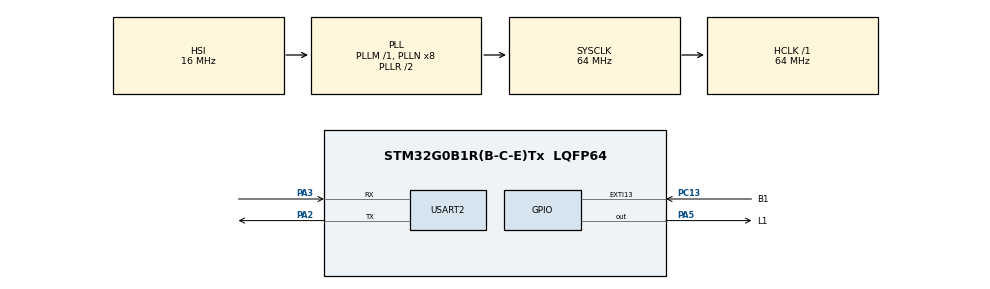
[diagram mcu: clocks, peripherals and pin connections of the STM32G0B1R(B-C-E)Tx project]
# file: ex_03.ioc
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Mcu.Family=STM32G0
Mcu.Name=STM32G0B1R(B-C-E)Tx
Mcu.Package=LQFP64
NVIC.EXTI4_15_IRQn=true\:0\:0\:false\:false\:true\:true\:true
NVIC.USART2_LPUART2_IRQn=true\:0\:0\:false\:false\:true\:true\:true
PA13.Mode=Serial_Wire
PA13.Signal=SYS_SWDIO
PA14-BOOT0.Mode=Serial_Wire
PA14-BOOT0.Signal=SYS_SWCLK
PA2.Mode=Asynchronous
PA2.Signal=USART2_TX
PA3.Mode=Asynchronous
PA3.Signal=USART2_RX
PA5.GPIO_Label=L1
PA5.PinState=GPIO_PIN_RESET
PA5.Signal=GPIO_Output
PC13.GPIO_Label=B1
PC13.GPIO_ModeDefaultEXTI=GPIO_MODE_IT_RISING_FALLING
PC13.Signal=GPXTI13
ProjectManager.HeapSize=0x200
ProjectManager.StackSize=0x400
ProjectManager.TargetToolchain=STM32CubeIDE
RCC.ADCFreq_Value=64000000
RCC.AHBFreq_Value=64000000
RCC.CortexFreq_Value=64000000
RCC.EXTERNAL_CLOCK_VALUE=48000
RCC.HCLKFreq_Value=64000000
RCC.HSE_VALUE=8000000
RCC.HSI48_VALUE=48000000
RCC.HSI_VALUE=16000000
RCC.LSE_VALUE=32768
RCC.SYSCLKFreq_VALUE=64000000
RCC.SYSCLKSource=RCC_SYSCLKSOURCE_PLLCLK
RCC.USBFreq_Value=48000000
RCC.VCOOutputFreq_Value=128000000
USART2.VirtualMode-Asynchronous=VM_ASYNC
VP_SYS_VS_DBSignals.Mode=DisableDeadBatterySignals
board=custom

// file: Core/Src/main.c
/* USER CODE BEGIN Header */
/**
  ******************************************************************************
  * @file           : main.c
  * @brief          : Main program body
  ******************************************************************************
  * @attention
  *
  * Copyright (c) 2022 STMicroelectronics.
  * All rights reserved.
  *
  * This software is licensed under terms that can be found in the LICENSE file
  * in the root directory of this software component.
  * If no LICENSE file comes with this software, it is provided AS-IS.
  *
  ******************************************************************************
  */
/* USER CODE END Header */
#include "main.h"

/* USER CODE BEGIN Includes */
#include<stdint.h>
#include<stdio.h>
#include<stdlib.h>
#include<string.h>
/* USER CODE END Includes */

/* USER CODE BEGIN PTD */
uint16_t count = 0;
uint8_t pres = 0;
char text[80];
/* USER CODE END PTD */

UART_HandleTypeDef huart2;

void SystemClock_Config(void);
static void MX_GPIO_Init(void);
static void MX_USART2_UART_Init(void);

/* USER CODE BEGIN 0 */
void HAL_GPIO_EXTI_Rising_Callback(uint16_t GPIO_Pin){
	count++;
	sprintf(text,"B1 presionado %d, ", count);
	HAL_UART_Transmit_IT(&huart2, &text, strlen(text));
}
/* USER CODE END 0 */

int main(void)
{

  /* MCU Configuration--------------------------------------------------------*/

  /* Reset of all peripherals, Initializes the Flash interface and the Systick. */
  HAL_Init();

  /* Configure the system clock */
  SystemClock_Config();

  /* Initialize all configured peripherals */
  MX_GPIO_Init();
  MX_USART2_UART_Init();

  /* Infinite loop */
  while (1)
  {

  }
}

void SystemClock_Config(void)
{
  RCC_OscInitTypeDef RCC_OscInitStruct = {0};
  RCC_ClkInitTypeDef RCC_ClkInitStruct = {0};

  /** Configure the main internal regulator output voltage
  */
  HAL_PWREx_ControlVoltageScaling(PWR_REGULATOR_VOLTAGE_SCALE1);
  /** Initializes the RCC Oscillators according to the specified parameters
  * in the RCC_OscInitTypeDef structure.
  */
  RCC_OscInitStruct.OscillatorType = RCC_OSCILLATORTYPE_HSI;
  RCC_OscInitStruct.HSIState = RCC_HSI_ON;
  RCC_OscInitStruct.HSIDiv = RCC_HSI_DIV1;
  RCC_OscInitStruct.HSICalibrationValue = RCC_HSICALIBRATION_DEFAULT;
  RCC_OscInitStruct.PLL.PLLState = RCC_PLL_ON;
  RCC_OscInitStruct.PLL.PLLSource = RCC_PLLSOURCE_HSI;
  RCC_OscInitStruct.PLL.PLLM = RCC_PLLM_DIV1;
  RCC_OscInitStruct.PLL.PLLN = 8;
  RCC_OscInitStruct.PLL.PLLP = RCC_PLLP_DIV2;
  RCC_OscInitStruct.PLL.PLLQ = RCC_PLLQ_DIV2;
  RCC_OscInitStruct.PLL.PLLR = RCC_PLLR_DIV2;
  if (HAL_RCC_OscConfig(&RCC_OscInitStruct) != HAL_OK)
  {
    Error_Handler();
  }
  /** Initializes the CPU, AHB and APB buses clocks
  */
  RCC_ClkInitStruct.ClockType = RCC_CLOCKTYPE_HCLK|RCC_CLOCKTYPE_SYSCLK
                              |RCC_CLOCKTYPE_PCLK1;
  RCC_ClkInitStruct.SYSCLKSource = RCC_SYSCLKSOURCE_PLLCLK;
  RCC_ClkInitStruct.AHBCLKDivider = RCC_SYSCLK_DIV1;
  RCC_ClkInitStruct.APB1CLKDivider = RCC_HCLK_DIV1;

  if (HAL_RCC_ClockConfig(&RCC_ClkInitStruct, FLASH_LATENCY_2) != HAL_OK)
  {
    Error_Handler();
  }
}

static void MX_USART2_UART_Init(void)
{

  huart2.Instance = USART2;
  huart2.Init.BaudRate = 115200;
  huart2.Init.WordLength = UART_WORDLENGTH_8B;
  huart2.Init.StopBits = UART_STOPBITS_1;
  huart2.Init.Parity = UART_PARITY_NONE;
  huart2.Init.Mode = UART_MODE_TX_RX;
  huart2.Init.HwFlowCtl = UART_HWCONTROL_NONE;
  huart2.Init.OverSampling = UART_OVERSAMPLING_16;
  huart2.Init.OneBitSampling = UART_ONE_BIT_SAMPLE_DISABLE;
  huart2.Init.ClockPrescaler = UART_PRESCALER_DIV1;
  huart2.AdvancedInit.AdvFeatureInit = UART_ADVFEATURE_NO_INIT;
  if (HAL_UART_Init(&huart2) != HAL_OK)
  {
    Error_Handler();
  }
  if (HAL_UARTEx_SetTxFifoThreshold(&huart2, UART_TXFIFO_THRESHOLD_1_8) != HAL_OK)
  {
    Error_Handler();
  }
  if (HAL_UARTEx_SetRxFifoThreshold(&huart2, UART_RXFIFO_THRESHOLD_1_8) != HAL_OK)
  {
    Error_Handler();
  }
  if (HAL_UARTEx_DisableFifoMode(&huart2) != HAL_OK)
  {
    Error_Handler();
  }

}

static void MX_GPIO_Init(void)
{
  GPIO_InitTypeDef GPIO_InitStruct = {0};

  /* GPIO Ports Clock Enable */
  __HAL_RCC_GPIOC_CLK_ENABLE();
  __HAL_RCC_GPIOA_CLK_ENABLE();

  /*Configure GPIO pin Output Level */
  HAL_GPIO_WritePin(L1_GPIO_Port, L1_Pin, GPIO_PIN_RESET);

  /*Configure GPIO pin : B1_Pin */
  GPIO_InitStruct.Pin = B1_Pin;
  GPIO_InitStruct.Mode = GPIO_MODE_IT_RISING_FALLING;
  GPIO_InitStruct.Pull = GPIO_NOPULL;
  HAL_GPIO_Init(B1_GPIO_Port, &GPIO_InitStruct);

  /*Configure GPIO pin : L1_Pin */
  GPIO_InitStruct.Pin = L1_Pin;
  GPIO_InitStruct.Mode = GPIO_MODE_OUTPUT_PP;
  GPIO_InitStruct.Pull = GPIO_NOPULL;
  GPIO_InitStruct.Speed = GPIO_SPEED_FREQ_LOW;
  HAL_GPIO_Init(L1_GPIO_Port, &GPIO_InitStruct);

  /* EXTI interrupt init*/
  HAL_NVIC_SetPriority(EXTI4_15_IRQn, 0, 0);
  HAL_NVIC_EnableIRQ(EXTI4_15_IRQn);

}

void Error_Handler(void)
{
  __disable_irq();
  while (1)
  {
  }
}
